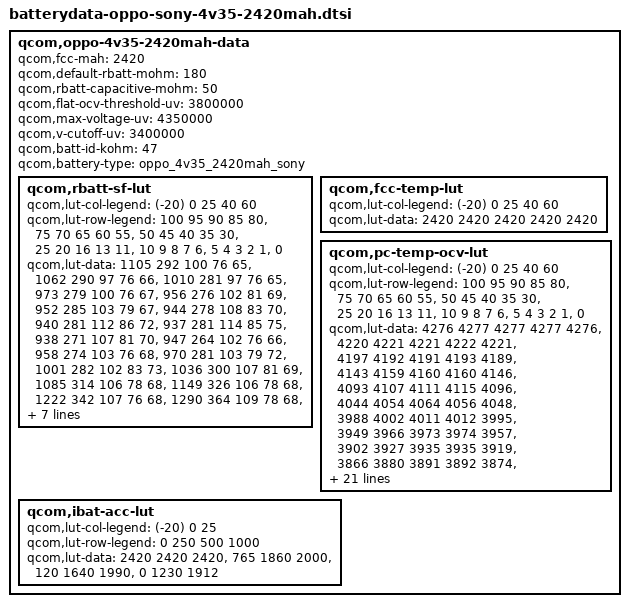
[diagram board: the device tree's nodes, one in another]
/* Copyright (c) 2013, The Linux Foundation. All rights reserved.
 *
 * This program is free software; you can redistribute it and/or modify
 * it under the terms of the GNU General Public License version 2 and
 * only version 2 as published by the Free Software Foundation.
 *
 * This program is distributed in the hope that it will be useful,
 * but WITHOUT ANY WARRANTY; without even the implied warranty of
 * MERCHANTABILITY or FITNESS FOR A PARTICULAR PURPOSE.  See the
 * GNU General Public License for more details.
 */

qcom,oppo-4v35-2420mah-data {
	qcom,fcc-mah = <2420>;
	qcom,default-rbatt-mohm = <180>;
	qcom,rbatt-capacitive-mohm = <50>;
	qcom,flat-ocv-threshold-uv = <3800000>;
	qcom,max-voltage-uv = <4350000>;
	qcom,v-cutoff-uv = <3400000>;
	qcom,batt-id-kohm = <47>;
	qcom,battery-type = "oppo_4v35_2420mah_sony";

	qcom,rbatt-sf-lut {
		qcom,lut-col-legend = <(-20) 0 25 40 60>;
		qcom,lut-row-legend = <100 95 90 85 80>,
				<75 70 65 60 55>,
				<50 45 40 35 30>,
				<25 20 16 13 11>,
				<10 9 8 7 6>,
				<5 4 3 2 1>,
				<0>;
		qcom,lut-data = <1105 292 100 76 65>,
				<1062 290 97 76	66>,
				<1010 281 97 76	65>,
				<973 279 100 76	67>,
				<956 276 102 81	69>,
				<952 285 103 79	67>,
				<944 278 108 83	70>,
				<940 281 112 86	72>,
				<937 281 114 85	75>,
				<938 271 107 81	70>,
				<947 264 102 76	66>,
				<958 274 103 76	68>,
				<970 281 103 79	72>,
				<1001 282 102 83 73>,
				<1036 300 107 81 69>,
				<1085 314 106 78 68>,
				<1149 326 106 78 68>,
				<1222 342 107 76 68>,
				<1290 364 109 78 68>,
				<1383 385 111 82 70>,
				<1421 401 115 85 71>,
				<1469 419 122 83 73>,
				<1522 438 127 88 74>,
				<1584 456 131 88 76>,
				<1600 483 132 86 75>,
				<1700 515 135 86 75>,
				<1800 565 142 88 78>,
				<1900 628 153 99 83>,
				<2000 738 171 101 90>,
				<5000 1000 232 126 106>,
				<135251 124940 59087 324 208>;
	};

	qcom,fcc-temp-lut {
		qcom,lut-col-legend = <(-20) 0 25 40 60>;
		qcom,lut-data = <2420 2420 2420 2420 2420>;
	};

	qcom,pc-temp-ocv-lut {
		qcom,lut-col-legend = <(-20) 0 25 40 60>;
		qcom,lut-row-legend = <100 95 90 85 80>,
				<75 70 65 60 55>,
				<50 45 40 35 30>,
				<25 20 16 13 11>,
				<10 9 8 7 6>,
				<5 4 3 2 1>,
				<0>;
		qcom,lut-data = <4276 4277 4277	4277 4276>,
				<4220 4221 4221	4222 4221>,
				<4197 4192 4191	4193 4189>,
				<4143 4159 4160	4160 4146>,
				<4093 4107 4111	4115 4096>,
				<4044 4054 4064	4056 4048>,
				<3988 4002 4011	4012 3995>,
				<3949 3966 3973	3974 3957>,
				<3902 3927 3935	3935 3919>,
				<3866 3880 3891	3892 3874>,
				<3838 3845 3853	3853 3840>,
				<3817 3824 3824	3828 3817>,
				<3801 3806 3806	3810 3799>,
				<3790 3792 3791	3795 3783>,
				<3781 3785 3779	3781 3761>,
				<3770 3774 3759	3759 3727>,
				<3749 3746 3738	3733 3706>,
				<3725 3714 3710	3704 3679>,
				<3706 3700 3688	3684 3661>,
				<3693 3693 3684	3683 3658>,
				<3688 3692 3683	3681 3655>,
				<3680 3689 3678	3675 3653>,
				<3670 3681 3673	3671 3648>,
				<3654 3668 3662	3661 3638>,
				<3638 3638 3635	3639 3613>,
				<3598 3591 3591	3598 3575>,
				<3547 3530 3536	3549 3528>,
				<3480 3447 3463	3485 3467>,
				<3393 3326 3364	3396 3390>,
				<3264 3206 3206	3270 3278>,
				<3000 3000 3000	3000 3000>;
	};

	qcom,ibat-acc-lut {
		qcom,lut-col-legend = <(-20) 0 25>;
		qcom,lut-row-legend = <0 250 500 1000>;
		qcom,lut-data = <2420 2420 2420>,
				<765 1860 2000>,
				<120 1640 1990>,
				<0 1230 1912>;
	};
};
